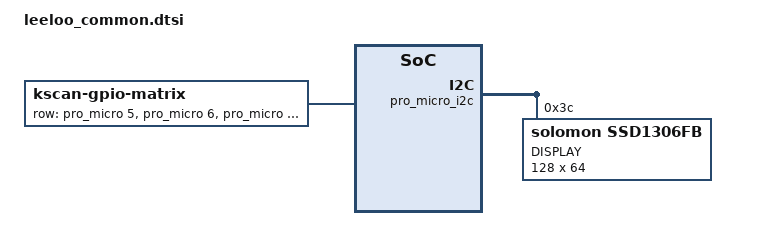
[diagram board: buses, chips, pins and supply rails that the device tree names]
/*
 * Copyright (c) 2023 The ZMK Contributors
 * SPDX-License-Identifier: MIT
 */


/ {
    chosen {
        zephyr,display = &oled;
        zmk,kscan = &kscan0;

    };
($row * 14) + $column
  


    kscan0: kscan {
        compatible = "zmk,kscan-gpio-matrix";
        label = "KSCAN";

        diode-direction = "col2row";

        row-gpios = <&pro_micro 5 (GPIO_ACTIVE_HIGH | GPIO_PULL_DOWN)>,
                    <&pro_micro 6 (GPIO_ACTIVE_HIGH | GPIO_PULL_DOWN)>,
                    <&pro_micro 7 (GPIO_ACTIVE_HIGH | GPIO_PULL_DOWN)>,
                    <&pro_micro 8 (GPIO_ACTIVE_HIGH | GPIO_PULL_DOWN)>;

    };

    left_encoder: left_encoder {
        compatible = "alps,ec11";
        label = "LEFT_ENCODER";
        a-gpios = <&pro_micro 21 (GPIO_ACTIVE_HIGH | GPIO_PULL_UP)>;
        b-gpios = <&pro_micro 20 (GPIO_ACTIVE_HIGH | GPIO_PULL_UP)>;
        steps = <120>;
        status = "disabled";
    };

    right_encoder: right_encoder {
        compatible = "alps,ec11";
        label = "RIGHT_ENCODER";
        a-gpios = <&pro_micro 20 (GPIO_ACTIVE_HIGH | GPIO_PULL_UP)>;
        b-gpios = <&pro_micro 21 (GPIO_ACTIVE_HIGH | GPIO_PULL_UP)>;
        steps = <120>;
        status = "disabled";
    };

    sensors {
        compatible = "zmk,keymap-sensors";
        sensors = <&left_encoder &right_encoder>;
        triggers-per-rotation = <30>;
    };

};

&pro_micro_i2c {
    status = "okay";

    oled: ssd1306@3c {
        compatible = "solomon,ssd1306fb";
        reg = <0x3c>;
        label = "DISPLAY";
        width = <128>;
        height = <64>;
        segment-offset = <0>;
        page-offset = <0>;
        display-offset = <0>;
        multiplex-ratio = <31>;
        segment-remap;
        com-invdir;
        com-sequential;
        prechargep = <0x22>;
    };
};
